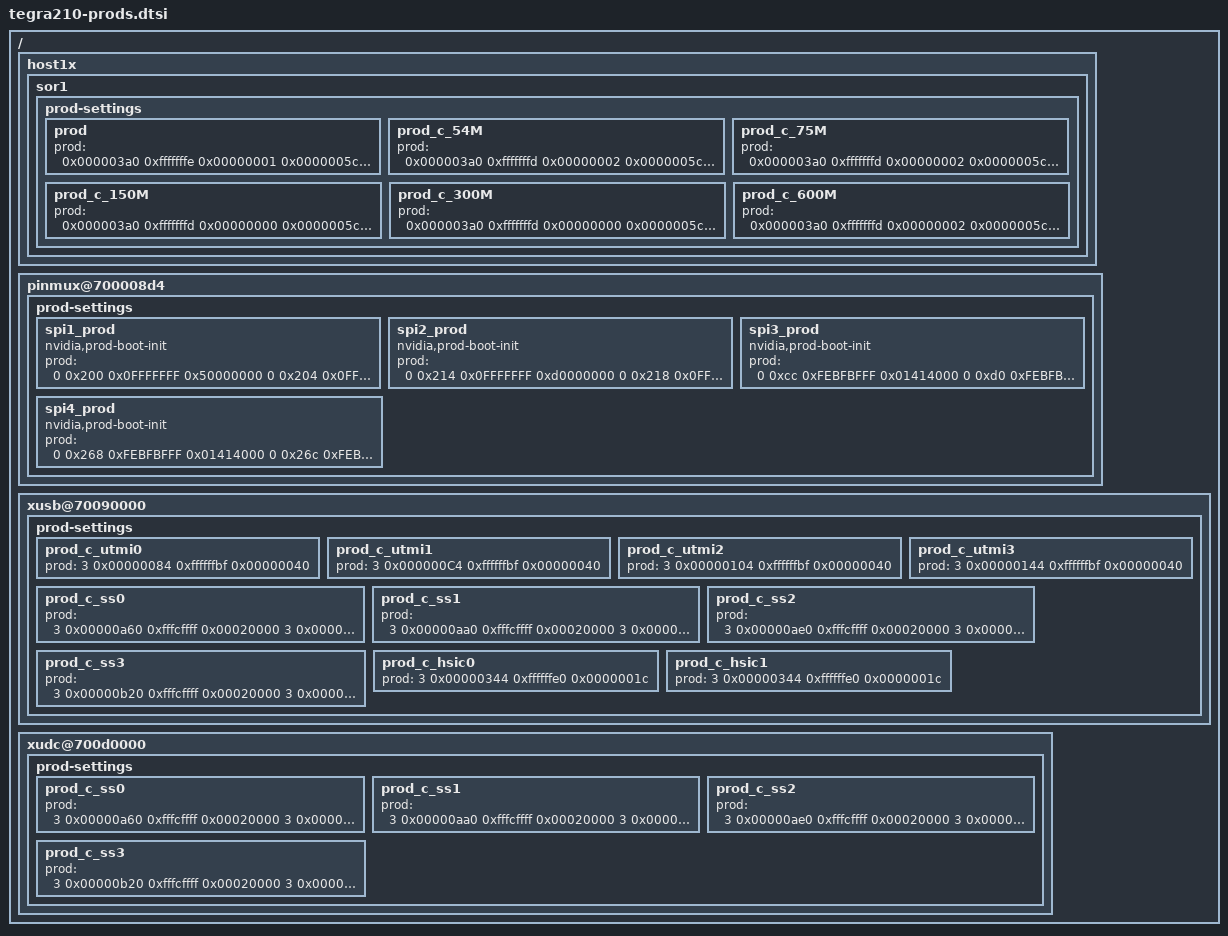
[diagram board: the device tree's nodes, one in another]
/*
 * Copyright (c) 2014, NVIDIA CORPORATION.  All rights reserved.
 *
 * This program is free software; you can redistribute it and/or modify
 * it under the terms of the GNU General Public License as published by
 * the Free Software Foundation; version 2 of the License.
 *
 * This program is distributed in the hope that it will be useful, but WITHOUT
 * ANY WARRANTY; without even the implied warranty of MERCHANTABILITY or
 * FITNESS FOR A PARTICULAR PURPOSE.  See the GNU General Public License for
 * more details.
 *
 * You should have received a copy of the GNU General Public License along
 * with this program; if not, write to the Free Software Foundation, Inc.,
 * 51 Franklin Street, Fifth Floor, Boston, MA  02110-1301, USA.
 *
 */

/ {
	host1x {
		sor1 {
			prod-settings {
				prod {
				    prod = <
					0x000003a0 0xfffffffe 0x00000001	// SOR_NV_PDISP_INPUT_CONTROL  	00:00=HDMI_SRC_SELECT	0x1
					0x0000005c 0xf0fff8ff 0x01000000	// SOR_NV_PDISP_SOR_PLL0_0	11:08=VCOCAP		0x0
										//				27:24=ICHPMP		0x1
					0x00000060 0xff0fe0ff 0x00300f80	// SOR_NV_PDISP_SOR_PLL1_0	08:08=TMDS_TERM		0x1
										//				12:09=TMDS_TERMADJ	0xf
										//				23:20=LOADADJ		0x3
					0x00000068 0xf0ffffff 0x09000000	// SOR_NV_PSIDP_SOR_PLL3_0	27:24=BG_VREF_LEVEL	0x9
					0x00000138 0x00000000 0x373f3f3f	// SOR_NV_PDISP_SOR_LANE_DRIVE_CURRENT0_0
										//				31:24=LANE3_DP_LANE3	0x37
										//				23:16=LANE2_DP_LANE0	0x3f
										//				15:08=LANE1_DP_LANE1	0x3f
										//				07:00=LANE0_DP_LANE2	0x3f
					0x00000148 0x00000000 0x00000000	// SOR_NV_PDISP_SOR_LANE_PREEMPHASIS0_0
										//				31:24=LANE3_DP_LANE3	0x00
										//				23:16=LANE2_DP_LANE0	0x00
										//				15:08=LANE1_DP_LANE1	0x00
										//				07:00=LANE0_DP_LANE2	0x00
					0x00000170 0xffbf00ff 0x00401000	// SOR_NV_PDISP_SOR_DP_PADCTL0_0
										//				22:22=TX_PU		0x1
										//				15:08=TX_PU_VALUE	0x10
				   >;
				};
				prod_c_54M {
				    prod = <
					0x000003a0 0xfffffffd 0x00000002	// SOR_NV_PDISP_INPUT_CONTROL  	01:01=ARM_VIDEO_RANGE	0x1
					0x0000005c 0xf0fff8ff 0x01000000	// SOR_NV_PDISP_SOR_PLL0_0	11:08=VCOCAP		0x0
										//				27:24=ICHPMP		0x1
					0x00000060 0xff0fe0ff 0x00300f80	// SOR_NV_PDISP_SOR_PLL1_0	08:08=TMDS_TERM		0x1
										//				12:09=TMDS_TERMADJ	0xf
										//				23:20=LOADADJ		0x3
					0x00000068 0xf0ffffff 0x09000000	// SOR_NV_PSIDP_SOR_PLL3_0	27:24=BG_VREF_LEVEL	0x9
					0x00000138 0x00000000 0x373f3f3f	// SOR_NV_PDISP_SOR_LANE_DRIVE_CURRENT0_0
										//				31:24=LANE3_DP_LANE3	0x37
										//				23:16=LANE2_DP_LANE0	0x3f
										//				15:08=LANE1_DP_LANE1	0x3f
										//				07:00=LANE0_DP_LANE2	0x3f
					0x00000148 0x00000000 0x00000000	// SOR_NV_PDISP_SOR_LANE_PREEMPHASIS0_0
										//				31:24=LANE3_DP_LANE3	0x00
										//				23:16=LANE2_DP_LANE0	0x00
										//				15:08=LANE1_DP_LANE1	0x00
										//				07:00=LANE0_DP_LANE2	0x00
					0x00000170 0xffbf00ff 0x00401000	// SOR_NV_PDISP_SOR_DP_PADCTL0_0
										//				22:22=TX_PU		0x1
										//				15:08=TX_PU_VALUE	0x10
				   >;
				};
				prod_c_75M {
				    prod = <
					0x000003a0 0xfffffffd 0x00000002	// SOR_NV_PDISP_INPUT_CONTROL  	01:01=ARM_VIDEO_RANGE	0x1
					0x0000005c 0xf0fff8ff 0x01000100	// SOR_NV_PDISP_SOR_PLL0_0	11:08=VCOCAP		0x1
										//				27:24=ICHPMP		0x1
					0x00000060 0xff0fe0ff 0x00300f80	// SOR_NV_PDISP_SOR_PLL1_0	08:08=TMDS_TERM		0x1
										//				12:09=TMDS_TERMADJ	0x9
										//				23:20=LOADADJ		0x3
					0x00000068 0xf0ffffff 0x09000000	// SOR_NV_PSIDP_SOR_PLL3_0	27:24=BG_VREF_LEVEL	0x9
					0x00000138 0x00000000 0x33373737	// SOR_NV_PDISP_SOR_LANE_DRIVE_CURRENT0_0
										//				31:24=LANE3_DP_LANE3	0x33
										//				23:16=LANE2_DP_LANE0	0x37
										//				15:08=LANE1_DP_LANE1	0x37
										//				07:00=LANE0_DP_LANE2	0x37
					0x00000148 0x00000000 0x00000000	// SOR_NV_PDISP_SOR_LANE_PREEMPHASIS0_0
										//				31:24=LANE3_DP_LANE3	0x00
										//				23:16=LANE2_DP_LANE0	0x00
										//				15:08=LANE1_DP_LANE1	0x00
										//				07:00=LANE0_DP_LANE2	0x00
					0x00000170 0xffbf00ff 0x00404000	// SOR_NV_PDISP_SOR_DP_PADCTL0_0
										//				22:22=TX_PU		0x1
										//				15:08=TX_PU_VALUE	0x40

				    >;
				};
				prod_c_150M {
				    prod = <
					0x000003a0 0xfffffffd 0x00000000	// SOR_NV_PDISP_INPUT_CONTROL  	01:01=ARM_VIDEO_RANGE	0x0
					0x0000005c 0xf0fff8ff 0x01000300	// SOR_NV_PDISP_SOR_PLL0_0	11:08=VCOCAP		0x3
										//				27:24=ICHPMP		0x1
					0x00000060 0xff0fe0ff 0x00300980	// SOR_NV_PDISP_SOR_PLL1_0	08:08=TMDS_TERM		0x1
										//				12:09=TMDS_TERMADJ	0x9
										//				23:20=LOADADJ		0x3
					0x00000068 0xf0ffffff 0x08000000	// SOR_NV_PSIDP_SOR_PLL3_0	27:24=BG_VREF_LEVEL	0x8
					0x00000138 0x00000000 0x33373737	// SOR_NV_PDISP_SOR_LANE_DRIVE_CURRENT0_0
										//				31:24=LANE3_DP_LANE3	0x33
										//				23:16=LANE2_DP_LANE0	0x3f
										//				15:08=LANE1_DP_LANE1	0x3f
										//				07:00=LANE0_DP_LANE2	0x3f
					0x00000148 0x00000000 0x00000000	// SOR_NV_PDISP_SOR_LANE_PREEMPHASIS0_0
										//				31:24=LANE3_DP_LANE3	0x00
										//				23:16=LANE2_DP_LANE0	0x00
										//				15:08=LANE1_DP_LANE1	0x00
										//				07:00=LANE0_DP_LANE2	0x00
					0x00000170 0xffbf00ff 0x00406600	// SOR_NV_PDISP_SOR_DP_PADCTL0_0
										//				22:22=TX_PU		0x1
										//				15:08=TX_PU_VALUE	0x66
				    >;
				};
				prod_c_300M {
				    prod = <
					0x000003a0 0xfffffffd 0x00000000	// SOR_NV_PDISP_INPUT_CONTROL  	01:01=ARM_VIDEO_RANGE	0x0
					0x0000005c 0xf0fff8ff 0x01000300	// SOR_NV_PDISP_SOR_PLL0_0	11:08=VCOCAP		0x3
										//				27:24=ICHPMP		0x1
					0x00000060 0xff0fe0ff 0x00300980	// SOR_NV_PDISP_SOR_PLL1_0	08:08=TMDS_TERM		0x1
										//				12:09=TMDS_TERMADJ	0x9
										//				23:20=LOADADJ		0x3
					0x00000068 0xf0ffffff 0x08000000	// SOR_NV_PSIDP_SOR_PLL3_0	27:24=BG_VREF_LEVEL	0x8
					0x00000138 0x00000000 0x33373737	// SOR_NV_PDISP_SOR_LANE_DRIVE_CURRENT0_0
										//				31:24=LANE3_DP_LANE3	0x33
										//				23:16=LANE2_DP_LANE0	0x37
										//				15:08=LANE1_DP_LANE1	0x37
										//				07:00=LANE0_DP_LANE2	0x37
					0x00000148 0x00000000 0x00171717	// SOR_NV_PDISP_SOR_LANE_PREEMPHASIS0_0
										//				31:24=LANE3_DP_LANE3	0x00
										//				23:16=LANE2_DP_LANE0	0x17
										//				15:08=LANE1_DP_LANE1	0x17
										//				07:00=LANE0_DP_LANE2	0x17
					0x00000170 0xffbf00ff 0x00406600	// SOR_NV_PDISP_SOR_DP_PADCTL0_0
										//				22:22=TX_PU		0x1
										//				15:08=TX_PU_VALUE	0x66
				    >;
				};
				prod_c_600M {
				    prod = <
					0x000003a0 0xfffffffd 0x00000002	// SOR_NV_PDISP_INPUT_CONTROL  	01:01=ARM_VIDEO_RANGE	0x1
					0x0000005c 0xf0fff8ff 0x01000300	// SOR_NV_PDISP_SOR_PLL0_0	11:08=VCOCAP		0x3
										//				27:24=ICHPMP		0x1
					0x00000060 0xff0fe0ff 0x00300980	// SOR_NV_PDISP_SOR_PLL1_0	08:08=TMDS_TERM		0x1
										//				12:09=TMDS_TERMADJ	0x9
										//				23:20=LOADADJ		0x3
					0x00000068 0xf0ffffff 0x08000000	// SOR_NV_PSIDP_SOR_PLL3_0	27:24=BG_VREF_LEVEL	0x8
					0x00000138 0x00000000 0x33373737	// SOR_NV_PDISP_SOR_LANE_DRIVE_CURRENT0_0
										//				31:24=LANE3_DP_LANE3	0x33
										//				23:16=LANE2_DP_LANE0	0x3f
										//				15:08=LANE1_DP_LANE1	0x3f
										//				07:00=LANE0_DP_LANE2	0x3f
					0x00000148 0x00000000 0x00000000	// SOR_NV_PDISP_SOR_LANE_PREEMPHASIS0_0
										//				31:24=LANE3_DP_LANE3	0x00
										//				23:16=LANE2_DP_LANE0	0x00
										//				15:08=LANE1_DP_LANE1	0x00
										//				07:00=LANE0_DP_LANE2	0x00
					0x00000170 0xffbf00ff 0x00406600	// SOR_NV_PDISP_SOR_DP_PADCTL0_0
										//				22:22=TX_PU		0x1
										//				15:08=TX_PU_VALUE	0x66
				   >;
				};
			};
		};
	};

	pinmux@700008d4 {
		prod-settings {
			#prod-cells = <4>;
			spi1_prod {
				nvidia,prod-boot-init;
				prod = <0 0x200 0x0FFFFFFF 0x50000000
					0 0x204 0x0FFFFFFF 0x50000000
					0 0x208 0x0FFFFFFF 0x50000000
					0 0x20c 0x0FFFFFFF 0x50000000
					0 0x210 0x0FFFFFFF 0x50000000
					1 0x50 0xFFFF1FF0 0x00006040
					1 0x54 0xFFFF1FF0 0x00006040
					1 0x58 0xFFFF1FF0 0x00006040
					1 0x5c 0xFFFF1FF0 0x00006040
					1 0x60 0xFFFF1FF0 0x00006040>;
			};
			spi2_prod {
				nvidia,prod-boot-init;
				prod = <0 0x214 0x0FFFFFFF 0xd0000000
					0 0x218 0x0FFFFFFF 0xd0000000
					0 0x21c 0x0FFFFFFF 0xd0000000
					0 0x220 0x0FFFFFFF 0xd0000000
					0 0x224 0x0FFFFFFF 0xd0000000
					1 0x64 0xFFFF1FF0 0x00006040
					1 0x68 0xFFFF1FF0 0x00006040
					1 0x6c 0xFFFF1FF0 0x00006040
					1 0x70 0xFFFF1FF0 0x00006040
					1 0x74 0xFFFF1FF0 0x00006040>;
			};
			spi3_prod {
				nvidia,prod-boot-init;
				prod = <0 0xcc 0xFEBFBFFF 0x01414000
					0 0xd0 0xFEBFBFFF 0x01414000
					0 0x140 0xFEBFBFFF 0x01414000
					0 0x144 0xFEBFBFFF 0x01414000>;
			};
			spi4_prod {
				nvidia,prod-boot-init;
				prod = <0 0x268 0xFEBFBFFF 0x01414000
					0 0x26c 0xFEBFBFFF 0x01414000
					0 0x270 0xFEBFBFFF 0x01414000
					0 0x274 0xFEBFBFFF 0x01414000>;
			};
		};
	};
	xusb@70090000 {
		prod-settings {
			#prod-cells = <4>;
			prod_c_utmi0 {
			    prod = <
				3 0x00000084 0xffffffbf 0x00000040
			    >;
			};
			prod_c_utmi1 {
			    prod = <
				3 0x000000C4 0xffffffbf 0x00000040
			    >;
			};
			prod_c_utmi2 {
			    prod = <
				3 0x00000104 0xffffffbf 0x00000040
			    >;
			};
			prod_c_utmi3 {
			    prod = <
				3 0x00000144 0xffffffbf 0x00000040
			    >;
			};
			prod_c_ss0 {
			    prod = <
				3 0x00000a60 0xfffcffff 0x00020000
				3 0x00000a64 0xffff0000 0x000000fc
				3 0x00000a68 0x00000000 0x00077f17
				3 0x00000a74 0x00000000 0xfcf01368
			    >;
			};
			prod_c_ss1 {
			    prod = <
				3 0x00000aa0 0xfffcffff 0x00020000
				3 0x00000aa4 0xffff0000 0x000000fc
				3 0x00000aa8 0x00000000 0x00077f17
				3 0x00000ab4 0x00000000 0xfcf01368
			    >;
			};
			prod_c_ss2 {
			    prod = <
				3 0x00000ae0 0xfffcffff 0x00020000
				3 0x00000ae4 0xffff0000 0x000000fc
				3 0x00000ae8 0x00000000 0x00077f17
				3 0x00000af4 0x00000000 0xfcf01368
			    >;
			};
			prod_c_ss3 {
			    prod = <
				3 0x00000b20 0xfffcffff 0x00020000
				3 0x00000b24 0xffff0000 0x000000fc
				3 0x00000b28 0x00000000 0x00077f17
				3 0x00000b34 0x00000000 0xfcf01368
			    >;
			};
			prod_c_hsic0 {
			    prod = <
				3 0x00000344 0xffffffe0 0x0000001c
			    >;
			};
			prod_c_hsic1 {
			    prod = <
				3 0x00000344 0xffffffe0 0x0000001c
			    >;
			};
		};
	};

	xudc@700d0000 {
		prod-settings {
			#prod-cells = <4>;
			prod_c_ss0 {
				prod = <
					3 0x00000a60 0xfffcffff 0x00020000	//UPHY_USB3_PAD_ECTL_1	17:16=TX_TERM_CTRL	0x2
					3 0x00000a64 0xffff0000 0x000000fc	//UPHY_USB3_PAD_ECTL_2	15:0=RX_CTLE		0xfc
					3 0x00000a68 0x00000000 0xc0077f1f	//UPHY_USB3_PAD_ECTL_3	31:0=RX_DFE		0xc0077f1f
					3 0x00000a6c 0x0000ffff 0x01c70000	//UPHY_USB3_PAD_ECTL_4	31:16=RX_CDR_CTRL	0x1c7
					3 0x00000a74 0x00000000 0xfcf01368	//UPHY_USB3_PAD_ECTL_6	31:0=RX_EQ_CTRL_H	0xfcf01368
				>;
			};
			prod_c_ss1 {
				prod = <
					3 0x00000aa0 0xfffcffff 0x00020000	//UPHY_USB3_PAD_ECTL_1	17:16=TX_TERM_CTRL	0x2
					3 0x00000aa4 0xffff0000 0x000000fc	//UPHY_USB3_PAD_ECTL_2	15:0=RX_CTLE		0xfc
					3 0x00000aa8 0x00000000 0xc0077f1f	//UPHY_USB3_PAD_ECTL_3	31:0=RX_DFE		0xc0077f1f
					3 0x00000aac 0x0000ffff 0x01c70000	//UPHY_USB3_PAD_ECTL_4	31:16=RX_CDR_CTRL	0x1c7
					3 0x00000ab4 0x00000000 0xfcf01368	//UPHY_USB3_PAD_ECTL_6	31:0=RX_EQ_CTRL_H	0xfcf01368
				>;
			};
			prod_c_ss2 {
				prod = <
					3 0x00000ae0 0xfffcffff 0x00020000	//UPHY_USB3_PAD_ECTL_1	17:16=TX_TERM_CTRL	0x2
					3 0x00000ae4 0xffff0000 0x000000fc	//UPHY_USB3_PAD_ECTL_2	15:0=RX_CTLE		0xfc
					3 0x00000ae8 0x00000000 0xc0077f1f	//UPHY_USB3_PAD_ECTL_3	31:0=RX_DFE		0xc0077f1f
					3 0x00000aec 0x0000ffff 0x01c70000	//UPHY_USB3_PAD_ECTL_4	31:16=RX_CDR_CTRL	0x1c7
					3 0x00000af4 0x00000000 0xfcf01368	//UPHY_USB3_PAD_ECTL_6	31:0=RX_EQ_CTRL_H	0xfcf01368
				>;
			};
			prod_c_ss3 {
				prod = <
					3 0x00000b20 0xfffcffff 0x00020000	//UPHY_USB3_PAD_ECTL_1	17:16=TX_TERM_CTRL	0x2
					3 0x00000b24 0xffff0000 0x000000fc	//UPHY_USB3_PAD_ECTL_2	15:0=RX_CTLE		0xfc
					3 0x00000b28 0x00000000 0xc0077f1f	//UPHY_USB3_PAD_ECTL_3	31:0=RX_DFE		0xc0077f1f
					3 0x00000b2c 0x0000ffff 0x01c70000	//UPHY_USB3_PAD_ECTL_4	31:16=RX_CDR_CTRL	0x1c7
					3 0x00000b34 0x00000000 0xfcf01368	//UPHY_USB3_PAD_ECTL_6	31:0=RX_EQ_CTRL_H	0xfcf01368
				>;
			};

		};

	};
};
